# f280015x_nmi_intrupt_regs register map
Vendor: Texas Instruments
Peripheral module from a debugger description file (folder C2000).
Address unit: 16 bits
Registers are 16-bit, read-write, no defined reset value unless marked. A register's access mark holds for its fields unless they carry their own. Offsets are as the file gives them; lines under a group give offsets from that group; [hi:lo] are bit positions; {n}, {i} and the like mark numbered series; 'fields as' and 'values as' point back to an identical list; <NAME> marks a mode.

## NMI_INTRUPT_REGS — NMI INTRUPT Registers
0x00 NMICFG — NMI Configuration Register
  [0] NMIE — Global NMI Enable
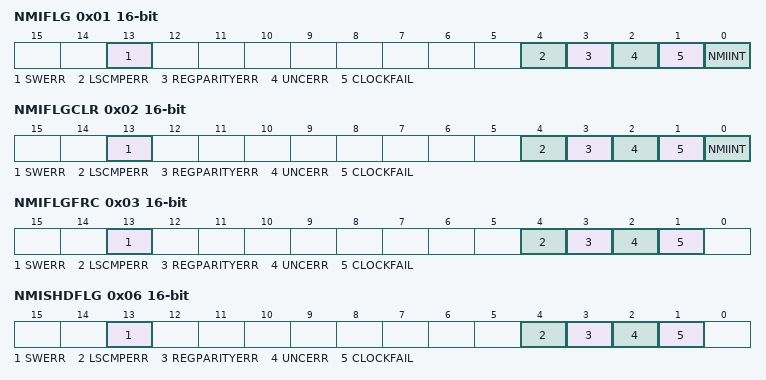
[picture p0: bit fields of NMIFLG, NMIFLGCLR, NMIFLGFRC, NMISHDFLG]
0x01 NMIFLG ro — NMI Flag Register (SYSRsn Clear)
  [13] SWERR — SW Error Force NMI Flag
  [4] LSCMPERR — Lockstep Compare Error
  [3] REGPARITYERR — Register parity error
  [2] UNCERR — Flash/RAM/ROM Uncorrectable Error NMI Flag
  [1] CLOCKFAIL — Clock Fail Interrupt Flag
  [0] NMIINT — NMI Interrupt Flag
0x02 NMIFLGCLR — NMI Flag Clear Register
  [13] SWERR — SW Error Flag Clear
  [4] LSCMPERR — Lockstep Compare Error flag clear
  [3] REGPARITYERR — Register parity error flag clear
  [2] UNCERR — Flash/RAM/ROM Uncorrectable Error NMI Flag clear
  [1] CLOCKFAIL — CLOCKFAIL Flag Clear
  [0] NMIINT — NMIINT Flag Clear
0x03 NMIFLGFRC — NMI Flag Force Register
  [13] SWERR — SW Error Flag Force
  [4] LSCMPERR — Lockstep Compare Error flag force
  [3] REGPARITYERR — Register parity error flag force
  [2] UNCERR — Flash/RAM/ROM Uncorrectable Error NMI Flag force
  [1] CLOCKFAIL — CLOCKFAIL Flag Force
0x04 NMIWDCNT ro — NMI Watchdog Counter Register
  [15:0] NMIWDCNT — NMI Watchdog Counter
0x05 NMIWDPRD — NMI Watchdog Period Register
  [15:0] NMIWDPRD — NMI Watchdog Period
0x06 NMISHDFLG ro — NMI Shadow Flag Register
  [13] SWERR — Shadow SW Error Flag
  [4] LSCMPERR — Lockstep Compare Error shadow flag
  [3] REGPARITYERR — Register parity error shadow flag
  [2] UNCERR — Flash/RAM/ROM Uncorrectable Error NMI shadow flag
  [1] CLOCKFAIL — Shadow CLOCKFAIL Flag
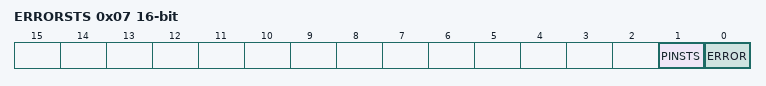
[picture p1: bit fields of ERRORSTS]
0x07 ERRORSTS ro — Error pin status
  [1] PINSTS — Error pin status.
  [0] ERROR — Error flag.
0x08 ERRORSTSCLR — ERRORSTS clear register
  [0] ERROR — ERRORFLG.ERROR clear bit
0x09 ERRORSTSFRC — ERRORSTS force register
  [0] ERROR — ERRORSTS.ERROR pin force.
0x0A ERRORCTL — Error pin control register
  [0] ERRORPOLSEL — ERROR pin polarity select
0x0B ERRORLOCK — Lock register to Error pin registers.
  [0] ERRORCTL — ERRORCTL Lock bit
